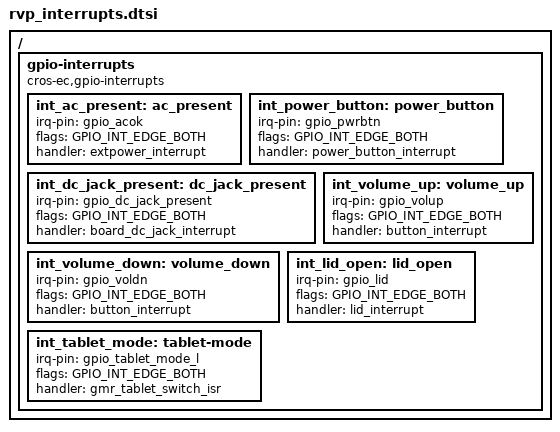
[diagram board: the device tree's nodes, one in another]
/* Copyright 2025 The ChromiumOS Authors
 * Use of this source code is governed by a BSD-style license that can be
 * found in the LICENSE file.
 */

/ {
	gpio-interrupts {
		compatible = "cros-ec,gpio-interrupts";

		int_ac_present: ac_present {
			irq-pin = <&gpio_acok>;
			flags = <GPIO_INT_EDGE_BOTH>;
			handler = "extpower_interrupt";
		};
		int_power_button: power_button {
			irq-pin = <&gpio_pwrbtn>;
			flags = <GPIO_INT_EDGE_BOTH>;
			handler = "power_button_interrupt";
		};
		int_dc_jack_present: dc_jack_present {
			irq-pin = <&gpio_dc_jack_present>;
			flags = <GPIO_INT_EDGE_BOTH>;
			handler = "board_dc_jack_interrupt";
		};
		int_volume_down: volume_down {
			irq-pin = <&gpio_voldn>;
			flags = <GPIO_INT_EDGE_BOTH>;
			handler = "button_interrupt";
		};
		int_volume_up: volume_up {
			irq-pin = <&gpio_volup>;
			flags = <GPIO_INT_EDGE_BOTH>;
			handler = "button_interrupt";
		};
		int_lid_open: lid_open {
			irq-pin = <&gpio_lid>;
			flags = <GPIO_INT_EDGE_BOTH>;
			handler = "lid_interrupt";
		};
		int_tablet_mode: tablet-mode {
			irq-pin = <&gpio_tablet_mode_l>;
			flags = <GPIO_INT_EDGE_BOTH>;
			handler = "gmr_tablet_switch_isr";
		};
	};
};
